# RA4M1 register map
Vendor: Renesas Electronics Corporation; Series: RA4; File version: 1.2
CPU: CM4 r0p1, little endian, MPU, FPU, VTOR, 4 interrupt priority bits
Registers are 8-bit, read-write, reset 0x0 unless marked. A register's access mark holds for its fields unless they carry their own. Offsets are from the block's base; [hi:lo] are bit positions; {n}, {i} and the like mark numbered series; 'fields as' and 'values as' point back to an identical list.

## POEG — Port Output Enable Module for GPT
Base 0x40042000
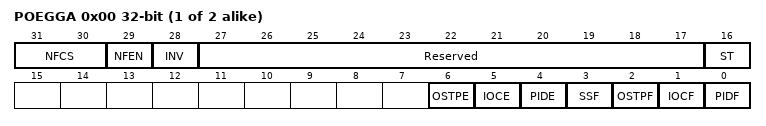
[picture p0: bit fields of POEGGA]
0x00 POEGG{x} (x=A,B; step 0x100) 32-bit — POEG Group {x} Setting Register
  [31:30] NFCS — Noise Filter Clock Select
    0=Sampling GTETRG pin input level for three times in every PCLKB; 1=Sampling GTETRG pin input level for three times in every PCLKB /8; 2=Sampling GTETRG pin input level for three times in every PCLKB /32; 3=Sampling GTETRG pin input level for three times in every PCLKB /128
  [29] NFEN — Noise Filter Enable
    0=Filtering noise disabled; 1=Filtering noise enabled
  [28] INV — GTETRG Input Reverse
    0=GTETRG Input; 1=GTETRG Input Reversed
  [27:17] Reserved — These bits are read as 00000000000. The write value should be 00000000000.
  [16] ST ro — GTETRG Input Status Flag
    0=GTETRG input after filtering is 0; 1=GTETRG input after filtering is 1
  [6] OSTPE — Oscillation Stop Detection Enable Note: Can be modified only once after a reset.
    0=A output-disable request from the oscillation stop detection disabled; 1=A output-disable request from the oscillation stop detection enabled
  [5] IOCE — Output-disable Request Enable from GPT Note: Can be modified only once after a reset.
    0=Output-disable request from the GPT disable request disabled; 1=Output-disable request from the GPT disable request enabled
  [4] PIDE — Port Input Detection Enable Note: Can be modified only once after a reset.
    0=Output-disable request from the GTETRG pins disabled; 1=Output-disable request from the GTETRG pins enabled
  [3] SSF — Software Stop Flag
    0=No output-disable request from software has occurred; 1=Output-disable request from software occurred
  [2] OSTPF write-0-clears read-modifies — Oscillation Stop Detection Flag
    0=No output-disable request from oscillation stop detection has occurred; 1=Output-disable request from oscillation stop detection occurred
  [1] IOCF write-0-clears read-modifies — Output-disable Request Detection Flag from GPT
    0=No output-disable request from the GPT disable request has occurred; 1=Output-disable request from the GPT disable request occurred
  [0] PIDF write-0-clears read-modifies — Port Input Detection Flag
    0=No output-disable request from the GTETRGn pin has occurred; 1=Output-disable request from the GTETRGn pin occurred

## SRAM — SRAM Control
Base 0x40002000
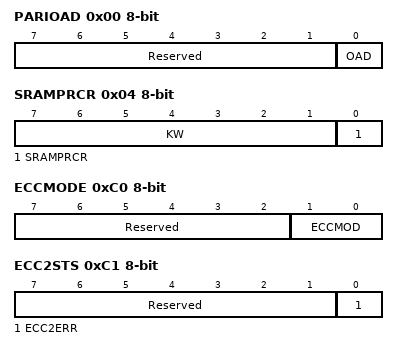
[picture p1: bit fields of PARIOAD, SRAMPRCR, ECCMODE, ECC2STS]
0x00 PARIOAD — SRAM Parity Error Operation After Detection Register
  [7:1] Reserved — These bits are read as 0000000. The write value should be 0000000.
  [0] OAD — Operation after Detection
    1=Reset; 0=Non maskable interrupt
0x04 SRAMPRCR — SRAM Protection Register
  [7:1] KW wo — Write Key Code
    120=Writing to the RAMPRCR bit is valid, when the KEY bits are written 1111000b; other=others (Writing to the RAMPRCR bit is invalid.)
  [0] SRAMPRCR — Register Write Control
    0=Disable writes to protected registers; 1=Enable writes to protected registers
0xC0 ECCMODE — ECC Operating Mode Control Register
  [7:2] Reserved — These bits are read as 000000. The write value should be 000000.
  [1:0] ECCMOD — ECC Operating Mode Select
    0=Disable ECC function; 1=Setting prohibited; 2=Enable ECC function without error checking; 3=Enable ECC function with error checking
0xC1 ECC2STS — ECC 2-Bit Error Status Register
  [7:1] Reserved — These bits are read as 0000000. The write value should be 0000000.
  [0] ECC2ERR write-0-clears read-modifies — ECC 2-Bit Error Status
    0=No 2-bit ECC error occurred; 1=2-bit ECC error occurred
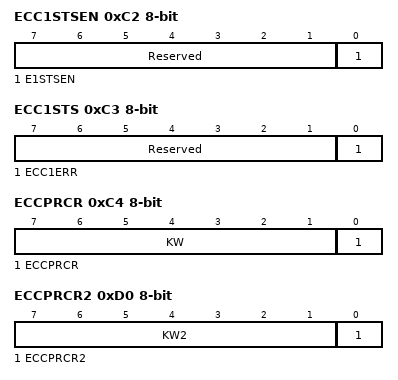
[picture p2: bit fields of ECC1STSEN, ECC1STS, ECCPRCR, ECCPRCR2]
0xC2 ECC1STSEN — ECC 1-Bit Error Information Update Enable Register
  [7:1] Reserved — These bits are read as 0000000. The write value should be 0000000.
  [0] E1STSEN — ECC 1-Bit Error Information Update Enable
    0=Disables updating of the 1-bit ECC error information; 1=Enables updating of the 1-bit ECC error information
0xC3 ECC1STS — ECC 1-Bit Error Status Register
  [7:1] Reserved — These bits are read as 0000000. The write value should be 0000000.
  [0] ECC1ERR write-0-clears read-modifies — ECC 1-Bit Error Status
    0=No 1-bit ECC error occurred; 1=1-bit ECC error occurred
0xC4 ECCPRCR — ECC Protection Register
  [7:1] KW wo — Write Key Code
    120=Writing to the ECCRAMPRCR bit is valid, when the KEY bits are written 1111000b; other=others (Writing to the ECCRAMPRCR bit is invalid.)
  [0] ECCPRCR — Register Write Control
    0=Disable writes to the protected registers; 1=Enable writes to the protected registers
0xD0 ECCPRCR2 — ECC Protection Register 2
  [7:1] KW2 wo — Write Key Code
    120=These bits enable or disable writes to the ECCPRCR2 bit; other=others (Writing to the ECCRAMPRCR2 bit is invalid.)
  [0] ECCPRCR2 — Register Write Control
    values as ECCPRCR.ECCPRCR
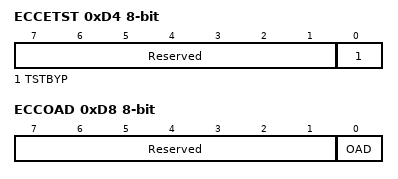
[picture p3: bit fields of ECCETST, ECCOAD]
0xD4 ECCETST — ECC Test Control Register
  [7:1] Reserved — These bits are read as 0000000. The write value should be 0000000.
  [0] TSTBYP — ECC Bypass Select
    0=ECC bypass disabled; 1=ECC bypass enabled
0xD8 ECCOAD — SRAM ECC Error Operation After Detection Register
  [7:1] Reserved — These bits are read as 0000000. The write value should be 0000000.
  [0] OAD — Operation after Detection
    0=Non-maskable interrupt; 1=Reset
